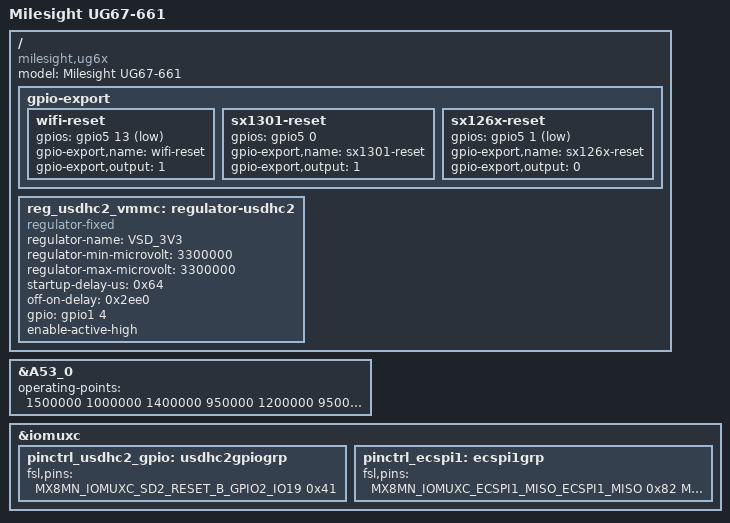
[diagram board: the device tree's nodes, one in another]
/dts-v1/;

#include "milesight-ug6x.dtsi"

/ {
	model = "Milesight UG67-661";
	compatible = "milesight,ug6x", "fsl,imx8mn";

	gpio-export {
		wifi-reset {
			gpios = <&gpio5 13 GPIO_ACTIVE_LOW>;
			gpio-export,name = "wifi-reset";
			gpio-export,output = <1>;
		};

		sx1301-reset {
			gpios = <&gpio5 0 (GPIO_ACTIVE_HIGH | GPIO_OPEN_DRAIN)>;
			gpio-export,name = "sx1301-reset";
			gpio-export,output = <1>;
		};

		sx126x-reset {
			gpios = <&gpio5 1 GPIO_ACTIVE_LOW>;
			gpio-export,name = "sx126x-reset";
			gpio-export,output = <0>;
		};
	};

        reg_usdhc2_vmmc: regulator-usdhc2 {
                compatible = "regulator-fixed";
                regulator-name = "VSD_3V3";
                regulator-min-microvolt = <3300000>;
                regulator-max-microvolt = <3300000>;
                startup-delay-us = <0x64>;
                off-on-delay = <0x2ee0>;
                gpio = <&gpio1 4 GPIO_ACTIVE_HIGH>;
                enable-active-high;
        };
};

&A53_0 {
	operating-points = <1500000 1000000 1400000 950000 1200000 950000>;
};

&iomuxc {
	pinctrl_usdhc2_gpio: usdhc2gpiogrp {
		fsl,pins = <
			MX8MN_IOMUXC_SD2_RESET_B_GPIO2_IO19     0x41 /* power_gpios_sd */
		>;
	};

	pinctrl_ecspi1: ecspi1grp {
		fsl,pins = <
			MX8MN_IOMUXC_ECSPI1_MISO_ECSPI1_MISO    0x82 /* SPI MISO */
			MX8MN_IOMUXC_ECSPI1_MOSI_ECSPI1_MOSI    0x82 /* SPI MOSI */
			MX8MN_IOMUXC_ECSPI1_SCLK_ECSPI1_SCLK    0x82 /* SPI SCLK */
			MX8MN_IOMUXC_SAI3_TXFS_GPIO4_IO31       0x19 /* SPI chip select SX-126x */
			MX8MN_IOMUXC_SAI3_MCLK_GPIO5_IO2        0x19 /* SPI chip select SX-1301 */
			MX8MN_IOMUXC_SAI3_RXFS_GPIO4_IO28       0x19 /* ? from decompiled ecspi1grp */
			MX8MN_IOMUXC_SAI3_RXC_GPIO4_IO29        0x19 /* ? from decompiled ecspi1grp */
			MX8MN_IOMUXC_ECSPI2_SCLK_GPIO5_IO10     0x19 /* ? from decompiled ecspi1grp */
			MX8MN_IOMUXC_ECSPI2_MOSI_GPIO5_IO11     0x19 /* ? from decompiled ecspi1grp */
			MX8MN_IOMUXC_NAND_READY_B_GPIO3_IO16    0x19 /* ? from decompiled ecspi1grp */
		>;
	};
};
